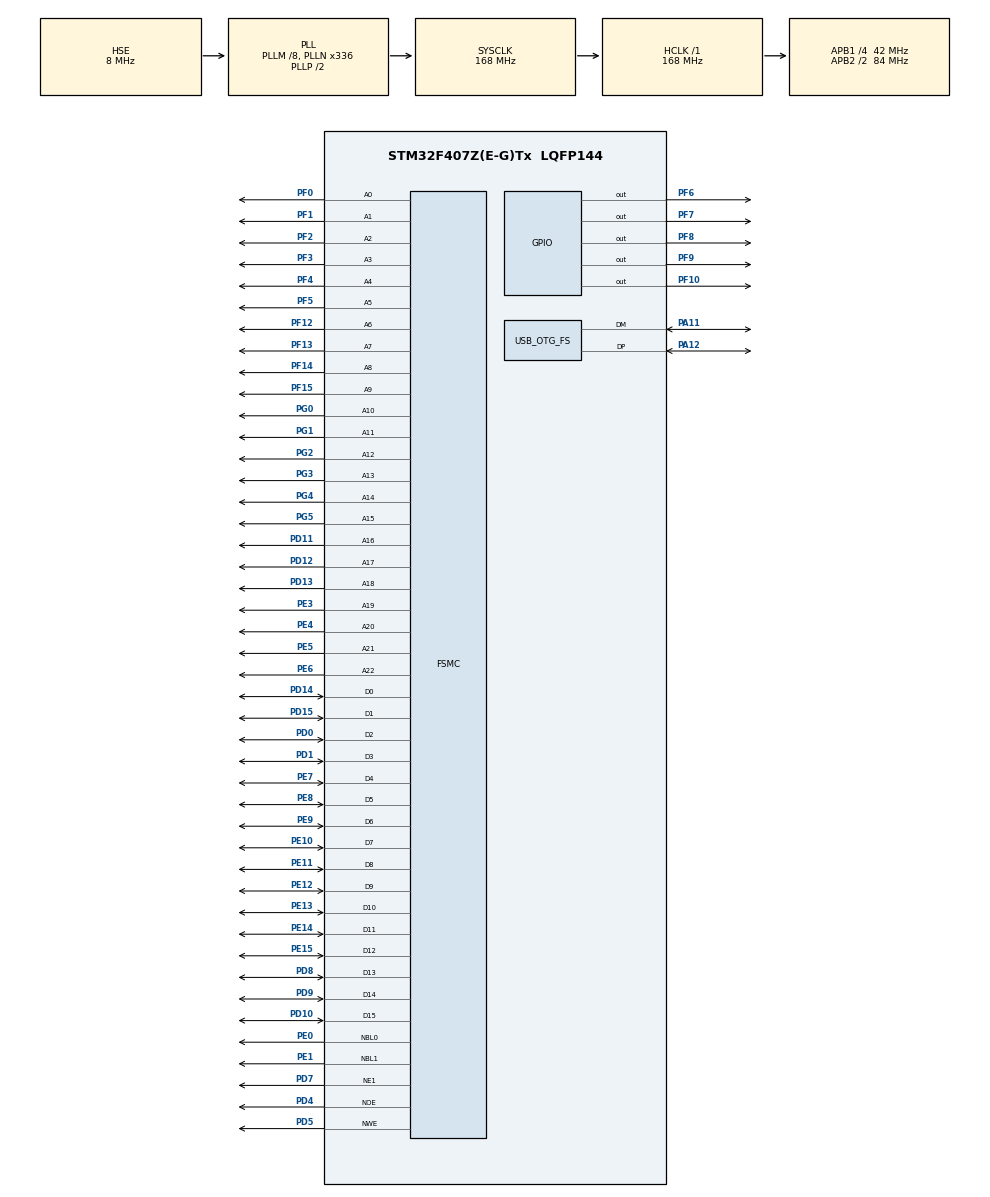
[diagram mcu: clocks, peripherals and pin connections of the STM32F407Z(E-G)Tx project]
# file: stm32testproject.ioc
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FSMC.WriteOperation1=FSMC_WRITE_OPERATION_ENABLE
Mcu.Family=STM32F4
Mcu.Name=STM32F407Z(E-G)Tx
Mcu.Package=LQFP144
NVIC.PriorityGroup=NVIC_PRIORITYGROUP_4
PA11.Mode=Host_Only
PA11.Signal=USB_OTG_FS_DM
PA12.Mode=Host_Only
PA12.Signal=USB_OTG_FS_DP
PA13.Mode=Serial_Wire
PA13.Signal=SYS_JTMS-SWDIO
PA14.Mode=Serial_Wire
PA14.Signal=SYS_JTCK-SWCLK
PC14-OSC32_IN.Mode=LSE-External-Oscillator
PC14-OSC32_IN.Signal=RCC_OSC32_IN
PC15-OSC32_OUT.Mode=LSE-External-Oscillator
PC15-OSC32_OUT.Signal=RCC_OSC32_OUT
PD0.Signal=FSMC_D2_DA2
PD1.Signal=FSMC_D3_DA3
PD10.Signal=FSMC_D15_DA15
PD11.Signal=FSMC_A16_CLE
PD12.Signal=FSMC_A17_ALE
PD13.Signal=FSMC_A18
PD14.Signal=FSMC_D0_DA0
PD15.Signal=FSMC_D1_DA1
PD4.Signal=FSMC_NOE
PD5.Signal=FSMC_NWE
PD7.Mode=NorPsramChipSelect1_1
PD7.Signal=FSMC_NE1
PD8.Signal=FSMC_D13_DA13
PD9.Signal=FSMC_D14_DA14
PE0.Signal=FSMC_NBL0
PE1.Signal=FSMC_NBL1
PE10.Signal=FSMC_D7_DA7
PE11.Signal=FSMC_D8_DA8
PE12.Signal=FSMC_D9_DA9
PE13.Signal=FSMC_D10_DA10
PE14.Signal=FSMC_D11_DA11
PE15.Signal=FSMC_D12_DA12
PE3.Signal=FSMC_A19
PE4.Signal=FSMC_A20
PE5.Signal=FSMC_A21
PE6.Signal=FSMC_A22
PE7.Signal=FSMC_D4_DA4
PE8.Signal=FSMC_D5_DA5
PE9.Signal=FSMC_D6_DA6
PF0.Signal=FSMC_A0
PF1.Signal=FSMC_A1
PF10.Signal=GPIO_Output
PF12.Signal=FSMC_A6
PF13.Signal=FSMC_A7
PF14.Signal=FSMC_A8
PF15.Signal=FSMC_A9
PF2.Signal=FSMC_A2
PF3.Signal=FSMC_A3
PF4.Signal=FSMC_A4
PF5.Signal=FSMC_A5
PF6.Signal=GPIO_Output
PF7.Signal=GPIO_Output
PF8.Signal=GPIO_Output
PF9.Signal=GPIO_Output
PG0.Signal=FSMC_A10
PG1.Signal=FSMC_A11
PG2.Signal=FSMC_A12
PG3.Signal=FSMC_A13
PG4.Signal=FSMC_A14
PG5.Signal=FSMC_A15
PH0-OSC_IN.Mode=HSE-External-Oscillator
PH0-OSC_IN.Signal=RCC_OSC_IN
PH1-OSC_OUT.Mode=HSE-External-Oscillator
PH1-OSC_OUT.Signal=RCC_OSC_OUT
ProjectManager.HeapSize=0x200
ProjectManager.StackSize=0x400
ProjectManager.TargetToolchain=CMake
RCC.48MHZClocksFreq_Value=48000000
RCC.AHBFreq_Value=168000000
RCC.APB1CLKDivider=RCC_HCLK_DIV4
RCC.APB1Freq_Value=42000000
RCC.APB1TimFreq_Value=84000000
RCC.APB2CLKDivider=RCC_HCLK_DIV2
RCC.APB2Freq_Value=84000000
RCC.APB2TimFreq_Value=168000000
RCC.CortexFreq_Value=168000000
RCC.HCLKFreq_Value=168000000
RCC.HSE_VALUE=8000000
RCC.HSI_VALUE=16000000
RCC.PLLM=8
RCC.PLLN=336
RCC.PLLQ=7
RCC.RCC_RTC_Clock_Source=RCC_RTCCLKSOURCE_LSI
RCC.RCC_RTC_Clock_SourceVirtual=RCC_RTCCLKSOURCE_LSE
RCC.RCC_RTC_Clock_Source_FROM_HSE=RCC_RTCCLKSOURCE_HSE_DIV31
RCC.SYSCLKFreq_VALUE=168000000
RCC.SYSCLKSource=RCC_SYSCLKSOURCE_PLLCLK
RCC.VCOOutputFreq_Value=336000000
SH.FSMC_A0.0=FSMC_A0,23b-a1
SH.FSMC_A1.0=FSMC_A1,23b-a1
SH.FSMC_A10.0=FSMC_A10,23b-a1
SH.FSMC_A11.0=FSMC_A11,23b-a1
SH.FSMC_A12.0=FSMC_A12,23b-a1
SH.FSMC_A13.0=FSMC_A13,23b-a1
SH.FSMC_A14.0=FSMC_A14,23b-a1
SH.FSMC_A15.0=FSMC_A15,23b-a1
SH.FSMC_A16_CLE.0=FSMC_A16,23b-a1
SH.FSMC_A17_ALE.0=FSMC_A17,23b-a1
SH.FSMC_A18.0=FSMC_A18,23b-a1
SH.FSMC_A19.0=FSMC_A19,23b-a1
SH.FSMC_A2.0=FSMC_A2,23b-a1
SH.FSMC_A20.0=FSMC_A20,23b-a1
SH.FSMC_A21.0=FSMC_A21,23b-a1
SH.FSMC_A22.0=FSMC_A22,23b-a1
SH.FSMC_A3.0=FSMC_A3,23b-a1
SH.FSMC_A4.0=FSMC_A4,23b-a1
SH.FSMC_A5.0=FSMC_A5,23b-a1
SH.FSMC_A6.0=FSMC_A6,23b-a1
SH.FSMC_A7.0=FSMC_A7,23b-a1
SH.FSMC_A8.0=FSMC_A8,23b-a1
SH.FSMC_A9.0=FSMC_A9,23b-a1
SH.FSMC_D0_DA0.0=FSMC_D0,16b-d1
SH.FSMC_D10_DA10.0=FSMC_D10,16b-d1
SH.FSMC_D11_DA11.0=FSMC_D11,16b-d1
SH.FSMC_D12_DA12.0=FSMC_D12,16b-d1
SH.FSMC_D13_DA13.0=FSMC_D13,16b-d1
SH.FSMC_D14_DA14.0=FSMC_D14,16b-d1
SH.FSMC_D15_DA15.0=FSMC_D15,16b-d1
SH.FSMC_D1_DA1.0=FSMC_D1,16b-d1
SH.FSMC_D2_DA2.0=FSMC_D2,16b-d1
SH.FSMC_D3_DA3.0=FSMC_D3,16b-d1
SH.FSMC_D4_DA4.0=FSMC_D4,16b-d1
SH.FSMC_D5_DA5.0=FSMC_D5,16b-d1
SH.FSMC_D6_DA6.0=FSMC_D6,16b-d1
SH.FSMC_D7_DA7.0=FSMC_D7,16b-d1
SH.FSMC_D8_DA8.0=FSMC_D8,16b-d1
SH.FSMC_D9_DA9.0=FSMC_D9,16b-d1
SH.FSMC_NBL0.0=FSMC_NBL0,2ByteEnable1
SH.FSMC_NBL1.0=FSMC_NBL1,2ByteEnable1
SH.FSMC_NOE.0=FSMC_NOE,Sram1
SH.FSMC_NWE.0=FSMC_NWE,Sram1
USB_OTG_FS.VirtualMode=Host_Only
USB_OTG_FS.phy_itface=HCD_PHY_EMBEDDED
VP_RTC_VS_RTC_Activate.Mode=RTC_Enabled
board=custom

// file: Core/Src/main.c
/* USER CODE BEGIN Header */
/**
  ******************************************************************************
  * @file           : main.c
  * @brief          : Main program body
  ******************************************************************************
  * @attention
  *
  * Copyright (c) 2026 STMicroelectronics.
  * All rights reserved.
  *
  * This software is licensed under terms that can be found in the LICENSE file
  * in the root directory of this software component.
  * If no LICENSE file comes with this software, it is provided AS-IS.
  *
  ******************************************************************************
  */
/* USER CODE END Header */
#include "main.h"

RTC_HandleTypeDef hrtc;

HCD_HandleTypeDef hhcd_USB_OTG_FS;

SRAM_HandleTypeDef hsram1;

void SystemClock_Config(void);
static void MX_GPIO_Init(void);
static void MX_RTC_Init(void);
static void MX_USB_OTG_FS_HCD_Init(void);
static void MX_FSMC_Init(void);

int main(void)
{

  /* MCU Configuration--------------------------------------------------------*/

  /* Reset of all peripherals, Initializes the Flash interface and the Systick. */
  HAL_Init();

  /* Configure the system clock */
  SystemClock_Config();

  /* Initialize all configured peripherals */
  MX_GPIO_Init();
  MX_RTC_Init();
  MX_USB_OTG_FS_HCD_Init();
  MX_FSMC_Init();
  /* USER CODE BEGIN 2 */

  volatile uint32_t *bsrr = &GPIOF->BSRR;
  SysTick->CTRL = 0;   // disable SysTick interrupt/
#define FPGA_BASE 0x60000000UL
#define FPGA16    ((volatile uint16_t *)FPGA_BASE)

  /* USER CODE END 2 */

  /* Infinite loop */
  while (1)
  {

 //    HAL_GPIO_TogglePin(GPIOF, GPIO_PIN_6);
 //    HAL_Delay(500);
 //     *bsrr = GPIO_PIN_6;
//      *bsrr = GPIO_PIN_6 << 16;

	//  unsigned int len = 128*1024; //128KB*4 = 512KB
	  unsigned int len = 512*1024; //2048KB
      for (unsigned int i=0;i!=len;++i)
      {
	      unsigned int val = ~i;
	      unsigned short vall = val&0xffff;
	      unsigned short valh = (val&0xffff0000)>>16;

	      FPGA16[i<<1] = vall;
	      FPGA16[(i<<1) +1] = valh;
      }

      for (unsigned int i=0;i!=len;++i)
      {
	      unsigned int val = ~i;

	      unsigned int datal = FPGA16[i<<1];
	      unsigned int datah = FPGA16[(i<<1) +1];
	      unsigned int data = (datah<<16) | datal;
	      if (data!=val)
	      {
		      FPGA16[0] = 0x1111;
		      FPGA16[0] = 0x2222;
		      FPGA16[0] = 0x3333;
		      FPGA16[0] = 0xffff;
		      FPGA16[0] = 0x1111;
		      FPGA16[0] = 0x2222;
		      FPGA16[0] = 0x3333;
		      FPGA16[0] = 0xffff;
		      FPGA16[0] = 0x1111;
		      FPGA16[0] = 0x2222;
		      FPGA16[0] = 0x3333;
		      FPGA16[0] = 0xffff;
	      }
      }

  }
}

void SystemClock_Config(void)
{
  RCC_OscInitTypeDef RCC_OscInitStruct = {0};
  RCC_ClkInitTypeDef RCC_ClkInitStruct = {0};

  /** Configure the main internal regulator output voltage
  */
  __HAL_RCC_PWR_CLK_ENABLE();
  __HAL_PWR_VOLTAGESCALING_CONFIG(PWR_REGULATOR_VOLTAGE_SCALE1);

  /** Initializes the RCC Oscillators according to the specified parameters
  * in the RCC_OscInitTypeDef structure.
  */
  RCC_OscInitStruct.OscillatorType = RCC_OSCILLATORTYPE_LSI|RCC_OSCILLATORTYPE_HSE;
  RCC_OscInitStruct.HSEState = RCC_HSE_ON;
  RCC_OscInitStruct.LSIState = RCC_LSI_ON;
  RCC_OscInitStruct.PLL.PLLState = RCC_PLL_ON;
  RCC_OscInitStruct.PLL.PLLSource = RCC_PLLSOURCE_HSE;
  RCC_OscInitStruct.PLL.PLLM = 8;
  RCC_OscInitStruct.PLL.PLLN = 336;
  RCC_OscInitStruct.PLL.PLLP = RCC_PLLP_DIV2;
  RCC_OscInitStruct.PLL.PLLQ = 7;
  if (HAL_RCC_OscConfig(&RCC_OscInitStruct) != HAL_OK)
  {
    Error_Handler();
  }

  /** Initializes the CPU, AHB and APB buses clocks
  */
  RCC_ClkInitStruct.ClockType = RCC_CLOCKTYPE_HCLK|RCC_CLOCKTYPE_SYSCLK
                              |RCC_CLOCKTYPE_PCLK1|RCC_CLOCKTYPE_PCLK2;
  RCC_ClkInitStruct.SYSCLKSource = RCC_SYSCLKSOURCE_PLLCLK;
  RCC_ClkInitStruct.AHBCLKDivider = RCC_SYSCLK_DIV1;
  RCC_ClkInitStruct.APB1CLKDivider = RCC_HCLK_DIV4;
  RCC_ClkInitStruct.APB2CLKDivider = RCC_HCLK_DIV2;

  if (HAL_RCC_ClockConfig(&RCC_ClkInitStruct, FLASH_LATENCY_5) != HAL_OK)
  {
    Error_Handler();
  }
}

static void MX_RTC_Init(void)
{

  /** Initialize RTC Only
  */
  hrtc.Instance = RTC;
  hrtc.Init.HourFormat = RTC_HOURFORMAT_24;
  hrtc.Init.AsynchPrediv = 127;
  hrtc.Init.SynchPrediv = 255;
  hrtc.Init.OutPut = RTC_OUTPUT_DISABLE;
  hrtc.Init.OutPutPolarity = RTC_OUTPUT_POLARITY_HIGH;
  hrtc.Init.OutPutType = RTC_OUTPUT_TYPE_OPENDRAIN;
  if (HAL_RTC_Init(&hrtc) != HAL_OK)
  {
    Error_Handler();
  }

}

static void MX_USB_OTG_FS_HCD_Init(void)
{

  hhcd_USB_OTG_FS.Instance = USB_OTG_FS;
  hhcd_USB_OTG_FS.Init.Host_channels = 8;
  hhcd_USB_OTG_FS.Init.speed = HCD_SPEED_FULL;
  hhcd_USB_OTG_FS.Init.dma_enable = DISABLE;
  hhcd_USB_OTG_FS.Init.phy_itface = HCD_PHY_EMBEDDED;
  hhcd_USB_OTG_FS.Init.Sof_enable = DISABLE;
  if (HAL_HCD_Init(&hhcd_USB_OTG_FS) != HAL_OK)
  {
    Error_Handler();
  }

}

static void MX_GPIO_Init(void)
{
  GPIO_InitTypeDef GPIO_InitStruct = {0};

  /* GPIO Ports Clock Enable */
  __HAL_RCC_GPIOE_CLK_ENABLE();
  __HAL_RCC_GPIOC_CLK_ENABLE();
  __HAL_RCC_GPIOF_CLK_ENABLE();
  __HAL_RCC_GPIOH_CLK_ENABLE();
  __HAL_RCC_GPIOG_CLK_ENABLE();
  __HAL_RCC_GPIOD_CLK_ENABLE();
  __HAL_RCC_GPIOA_CLK_ENABLE();

  /*Configure GPIO pin Output Level */
  HAL_GPIO_WritePin(GPIOF, GPIO_PIN_6|GPIO_PIN_7|GPIO_PIN_8|GPIO_PIN_9
                          |GPIO_PIN_10, GPIO_PIN_RESET);

  /*Configure GPIO pins : PF6 PF7 PF8 PF9
                           PF10 */
  GPIO_InitStruct.Pin = GPIO_PIN_6|GPIO_PIN_7|GPIO_PIN_8|GPIO_PIN_9
                          |GPIO_PIN_10;
  GPIO_InitStruct.Mode = GPIO_MODE_OUTPUT_PP;
  GPIO_InitStruct.Pull = GPIO_NOPULL;
  GPIO_InitStruct.Speed = GPIO_SPEED_FREQ_LOW;
  HAL_GPIO_Init(GPIOF, &GPIO_InitStruct);

}

/* FSMC initialization function */
static void MX_FSMC_Init(void)
{

  FSMC_NORSRAM_TimingTypeDef Timing = {0};

  /** Perform the SRAM1 memory initialization sequence
  */
  hsram1.Instance = FSMC_NORSRAM_DEVICE;
  hsram1.Extended = FSMC_NORSRAM_EXTENDED_DEVICE;
  /* hsram1.Init */
  hsram1.Init.NSBank = FSMC_NORSRAM_BANK1;
  hsram1.Init.DataAddressMux = FSMC_DATA_ADDRESS_MUX_DISABLE;
  hsram1.Init.MemoryType = FSMC_MEMORY_TYPE_SRAM;
  hsram1.Init.MemoryDataWidth = FSMC_NORSRAM_MEM_BUS_WIDTH_16;
  hsram1.Init.BurstAccessMode = FSMC_BURST_ACCESS_MODE_DISABLE;
  hsram1.Init.WaitSignalPolarity = FSMC_WAIT_SIGNAL_POLARITY_LOW;
  hsram1.Init.WrapMode = FSMC_WRAP_MODE_DISABLE;
  hsram1.Init.WaitSignalActive = FSMC_WAIT_TIMING_BEFORE_WS;
  hsram1.Init.WriteOperation = FSMC_WRITE_OPERATION_ENABLE;
  hsram1.Init.WaitSignal = FSMC_WAIT_SIGNAL_DISABLE;
  hsram1.Init.ExtendedMode = FSMC_EXTENDED_MODE_DISABLE;
  hsram1.Init.AsynchronousWait = FSMC_ASYNCHRONOUS_WAIT_DISABLE;
  hsram1.Init.WriteBurst = FSMC_WRITE_BURST_DISABLE;
  hsram1.Init.PageSize = FSMC_PAGE_SIZE_NONE;
  /* Timing */
  Timing.AddressSetupTime = 15;
  Timing.AddressHoldTime = 15;
  Timing.DataSetupTime = 255;
  Timing.BusTurnAroundDuration = 15;
  Timing.CLKDivision = 16;
  Timing.DataLatency = 17;
  Timing.AccessMode = FSMC_ACCESS_MODE_A;
  /* ExtTiming */

  if (HAL_SRAM_Init(&hsram1, &Timing, NULL) != HAL_OK)
  {
    Error_Handler( );
  }

}

void Error_Handler(void)
{
  __disable_irq();
  while (1)
  {
  }
}
